# STM32WL30 register map
File version: 1.0
CPU: CM0+ r0p0, little endian, MPU, no FPU, 4 interrupt priority bits
Registers are 32-bit, read-write, reset 0x0 unless marked. A register's access mark holds for its fields unless they carry their own. Offsets are from the block's base; [hi:lo] are bit positions.

## TIM16 — TIM16 address block description
Base 0x40005000
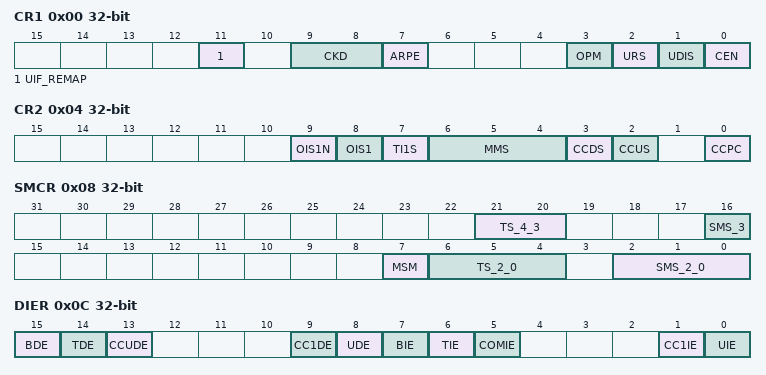
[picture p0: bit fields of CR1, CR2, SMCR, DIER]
0x00 CR1 (reset mask 0xF)
  [11] UIF_REMAP — UIFREMAP: UIF status bit remapping 0: No remapping. UIF status bit is not copied to TIMx_CNT register bit 31. 1: Remapping enabled. UIF status bit is copied to TIMx_CNT register bit 31.
  [9:8] CKD — CKD[1:0]: Clock division This bit-field indicates the division ratio between the timer clock (CK_INT) frequency and the dead-time and sampling clock (tDTS)used by the dead-time generators and the digital filters (TIx), 00: tDTS=tCK_INT 01: tDTS=2*tCK_INT 10: tDTS=4*tCK_INT 11: Reserved, do not program this value
  [7] ARPE — ARPE: Auto-reload preload enable 0: TIMx_ARR register is not buffered 1: TIMx_ARR register is buffered
  [3] OPM — OPM: One pulse mode 0: Counter is not stopped at update event. 1: Counter stops counting at the next update event (clearing the bit CEN)
  [2] URS — URS: Update request source This bit is set and cleared by software to select the UEV event sources. 0: Any of the following events generate an update interrupt or DMA request if enabled. These events can be: - Counter overflow/underflow - Setting the UG bit - Update generation through the slave mode controller 1: Only counter overflow/underflow generates an update interrupt or DMA request if enabled.
  [1] UDIS — UDIS: Update disable This bit is set and cleared by software to enable/disable UEV event generation. 0: UEV enabled. The Update (UEV) event is generated by one of the following events: - Counter overflow/underflow - Setting the UG bit - Update generation through the slave mode controller Buffered registers are then loaded with their preload values. 1: UEV disabled. The Update event is not generated, shadow registers keep their value (ARR, PSC, CCRx). However the counter and the prescaler are reinitialized if the UG bit is set or if a hardware reset is received from the slave mode controller.
  [0] CEN — CEN: Counter enable 0: Counter disabled 1: Counter enabled Note: External clock and gated mode can work only if the CEN bit has been previously set by software. However trigger mode can set the CEN bit automatically by hardware.
0x04 CR2 (reset mask 0xF)
  [9] OIS1N — OIS1N: Output Idle state 1 (OC1N output) 0: OC1N=0 after a dead-time when MOE=0 1: OC1N=1 after a dead-time when MOE=0 Note: This bit can not be modified as long as LOCK level 1, 2 or 3 has been programmed (LOCK bits in TIMx_BKR register).
  [8] OIS1 — OIS1: Output Idle state 1 (OC1 output) 0: OC1=0 (after a dead-time if OC1N is implemented) when MOE=0 1: OC1=1 (after a dead-time if OC1N is implemented) when MOE=0 Note: This bit can not be modified as long as LOCK level 1, 2 or 3 has been programmed (LOCK bits in TIMx_BKR register).
  [7] TI1S — TI1S: TI1 selection 0: The TIMx_CH1 pin is connected to TI1 input 1: Reserved
  [6:4] MMS — MMS[2:0]: Master mode selection These bits allow to select the information to be sent in master mode to slave timers for synchronization (TRGO). The combination is as follows: 000: Reset - the UG bit from the TIMx_EGR register is used as trigger output (TRGO). If the reset is generated by the trigger input (slave mode controller configured in reset mode) then the signal on TRGO is delayed compared to the actual reset. 001: Enable - the Counter Enable signal CNT_EN is used as trigger output (TRGO). It is useful to start several timers at the same time or to control a window in which a slave timer is enable. The Counter Enable signal is generated by a logic OR between CEN control bit and the trigger input when configured in gated mode. When the Counter Enable signal is controlled by the trigger input, there is a delay on TRGO, except if the master/slave mode is selected (see the MSM bit description in TIMx_SMCR register). 010: Update - The update event is selected as trigger output (TRGO). For instance a master timer can then be used as a prescaler for a slave timer. 011: Compare Pulse - The trigger output send a positive pulse when the CC1IF flag is to be set (even if it was already high), as soon as a capture or a compare match occurred. (TRGO). 100: Compare - OC1REF signal is used as trigger output (TRGO).
  [3] CCDS — CCDS: Capture/compare DMA selection 0: CCx DMA request sent when CCx event occurs 1: CCx DMA requests sent when update event occurs
  [2] CCUS — CCUS: Capture/compare control update selection 0: When capture/compare control bits are preloaded (CCPC=1), they are updated by setting the COMG bit only. 1: When capture/compare control bits are preloaded (CCPC=1), they are updated by setting the COMG bit or when an rising edge occurs on TRGI. Note: This bit acts only on channels that have a complementary output.
  [0] CCPC — CCPC: Capture/compare preloaded control 0: CCxE, CCxNE and OCxM bits are not preloaded 1: CCxE, CCxNE and OCxM bits are preloaded, after having been written, they are updated only when COM bit is set. Note: This bit acts only on channels that have a complementary output.
0x08 SMCR (reset mask 0xF)
  [21:20] TS_4_3 — TS[4:0]: Trigger selection. See TS_LSB description
  [16] SMS_3 — SMS[3:0]: Slave mode selection. See SMS_LSB description
  [7] MSM — MSM: Master/slave mode 0: No action 1: The effect of an event on the trigger input (TRGI) is delayed to allow a perfect synchronization between the current timer and its slaves (through TRGO). It is useful if we want to synchronize several timers on a single external event.
  [6:4] TS_2_0 — TS[4:0]: Trigger selection This bitfield selects the trigger input to be used to synchronize the counter. 00000: Internal Trigger 0 (ITR0) 00001: Internal Trigger 1 (ITR1) 00010: Internal Trigger 2 (ITR2) 00011: Internal Trigger 3 (ITR3) 00100: TI1 Edge Detector (TI1F_ED) 00101: Filtered Timer Input 1 (TI1FP1) Other codes: Reserved Note: These bits must be changed only when they are not used (e.g. when SMS=000) to avoid wrong edge detections at the transition. See Table 79 in IUM: TIM16 register map and reset values on page 469 for more details on ITRx meaning for each Timer.
  [2:0] SMS_2_0 — SMS[3:0]: Slave mode selection When external signals are selected the active edge of the trigger signal (TRGI) is linked to the polarity selected on the external input (see Input Control register and Control Register description.
0x0C DIER (reset mask 0xF)
  [15] BDE — BDE: Break DMA request Enable. Not used in Blue51. Not available in IUM 0: Break DMA request disabled. 1: Break DMA request enabled.
  [14] TDE — TDE: Trigger DMA request enable 0: Trigger DMA request disabled 1: Trigger DMA request enabled
  [13] CCUDE — CCUDE: CC-Update DMA request Enable. Not used in Blue51. Not available in IUM 0: CC-Update DMA request disabled. 1: CC-Update DMA request enabled.
  [9] CC1DE — CC1DE: Capture/Compare 1 DMA request enable 0: CC1 DMA request disabled 1: CC1 DMA request enabled
  [8] UDE — UDE: Update DMA request enable 0: Update DMA request disabled 1: Update DMA request enabled
  [7] BIE — BIE: Break interrupt enable 0: Break interrupt disabled 1: Break interrupt enabled
  [6] TIE — TIE: Trigger interrupt enable 0: Trigger interrupt disabled 1: Trigger interrupt enabled
  [5] COMIE — COMIE: COM interrupt enable 0: COM interrupt disabled 1: COM interrupt enabled
  [1] CC1IE — CC1IE: Capture/Compare 1 interrupt enable 0: CC1 interrupt disabled. 1: CC1 interrupt enabled
  [0] UIE — UIE: Update interrupt enable 0: Update interrupt disabled 1: Update interrupt enabled
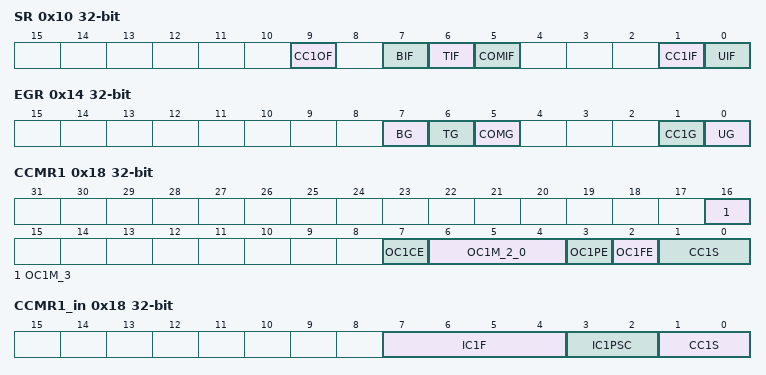
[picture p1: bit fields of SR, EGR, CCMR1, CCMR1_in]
0x10 SR (reset mask 0xF)
  [9] CC1OF — CC1OF: Capture_Compare 1 overcapture flag This flag is set by hardware only when the corresponding channel is configured in input capture mode. It is cleared by software by writing it to '0'. 0: No overcapture has been detected 1: The counter value has been captured in TIMx_CCR1 register while CC1IF flag was already set
  [7] BIF — BIF: Break interrupt flag This flag is set by hardware as soon as the break input goes active. It can be cleared by software if the break input is not active. 0: No break event occurred 1: An active level has been detected on the break input
  [6] TIF — TIF: Trigger interrupt flag This flag is set by hardware on trigger event (active edge detected on TRGI input when the slave mode controller is enabled in all modes but gated mode, both edges in case gated mode is selected). It is cleared by software. 0: No trigger event occurred 1: Trigger interrupt pending
  [5] COMIF — COMIF: COM interrupt flag This flag is set by hardware on a COM event (once the capture compare control bits CCxE, CCxNE, OCxMhave been updated). It is cleared by software. 0: No COM event occurred 1: COM interrupt pending
  [1] CC1IF — CC1IF: Capture/Compare 1 interrupt flag If channel CC1 is configured as output: This flag is set by hardware when the counter matches the compare value. It is cleared by software. 0: No match. 1: The content of the counter TIMx_CNT matches the content of the TIMx_CCR1 register. When the contents of TIMx_CCR1 are greater than the contents of TIMx_ARR, the CC1IF bit goes high on the counter overflow If channel CC1 is configured as input: This bit is set by hardware on a capture. It is cleared by software or by reading the TIMx_CCR1 register. 0: No input capture occurred 1: The counter value has been captured in TIMx_CCR1 register (An edge has been detected on IC1 which matches the selected polarity)
  [0] UIF — UIF: Update interrupt flag This bit is set by hardware on an update event. It is cleared by software. 0: No update occurred. 1: Update interrupt pending. This bit is set by hardware when the registers are updated: At overflow regarding the repetition counter value (update if repetition counter = 0) and if the UDIS=0 in the TIMx_CR1 register. When CNT is reinitialized by software using the UG bit in TIMx_EGR register, if URS=0 and UDIS=0 in the TIMx_CR1 register.
0x14 EGR (reset mask 0xF)
  [7] BG wo — BG: Break generation This bit is set by software in order to generate an event, it is automatically cleared by hardware. 0: No action. 1: A break event is generated. MOE bit is cleared and BIF flag is set. Related interrupt or DMA transfer can occur if enabled.
  [6] TG wo — TG: Trigger generation This bit is set by software in order to generate an event, it is automatically cleared by hardware. 0: No action 1: The TIF flag is set in TIMx_SR register. Related interrupt or DMA transfer can occur if enabled
  [5] COMG wo — COMG: Capture/Compare control update generation This bit can be set by software, it is automatically cleared by hardware. 0: No action 1: When the CCPC bit is set, it is possible to update the CCxE, CCxNE and OCxM bits Note: This bit acts only on channels that have a complementary output.
  [1] CC1G wo — CC1G: Capture/Compare 1 generation This bit is set by software in order to generate an event, it is automatically cleared by hardware. 0: No action. 1: A capture/compare event is generated on channel 1: If channel CC1 is configured as output: CC1IF flag is set, Corresponding interrupt or DMA request is sent if enabled. If channel CC1 is configured as input: The current value of the counter is captured in TIMx_CCR1 register. The CC1IF flag is set, the corresponding interrupt or DMA request is sent if enabled. The CC1OF flag is set if the CC1IF flag was already high.
  [0] UG wo — UG: Update generation This bit can be set by software, it is automatically cleared by hardware. 0: No action. 1: Reinitialize the counter and generates an update of the registers. Note that the prescaler counter is cleared too (anyway the prescaler ratio is not affected).
0x18 CCMR1 (reset mask 0xF)
  [16] OC1M_3 — OC1M[3]: Output Compare 1 mode (bit 3)
  [7] OC1CE — OC1CE: Output Compare 1 Clear Enable. Not used in Blue51. Not available in IUM 0: OC1REF is not affected by the ocref_clr_int signal. 1: OC1REF is cleared as soon as a high level is detected on the ocref_clr_int signal.
  [6:4] OC1M_2_0 — OC1M[2:0]: Output Compare 1 mode (bits 2 to 0) These bits define the behavior of the output reference signal OC1REF from which OC1 and OC1N are derived. OC1REF is active high whereas OC1 and OC1N active level depends on CC1P and CC1NP bits.
  [3] OC1PE — OC1PE: Output Compare 1 preload enable 0: Preload register on TIMx_CCR1 disabled. TIMx_CCR1 can be written at anytime, the new value is taken in account immediately.. 1: Preload register on TIMx_CCR1 enabled. Read/Write operations access the preload register. TIMx_CCR1 preload value is loaded in the active register at each update event. Note: 1: These bits can not be modified as long as LOCK level 3 has been programmed (LOCK bits in TIMx_BDTR register) and CC1S='00' (the channel is configured in output). Note: 2: The PWM mode can be used without validating the preload register only in one pulse mode (OPM bit set in TIMx_CR1 register). Else the behavior is not guaranteed.
  [2] OC1FE — OC1FE: Output Compare 1 fast enable This bit is used to accelerate the effect of an event on the trigger in input on the CC output. 0: CC1 behaves normally depending on counter and CCR1 values even when the trigger is ON. The minimum delay to activate CC1 output when an edge occurs on the trigger input is 5 clock cycles. 1: An active edge on the trigger input acts like a compare match on CC1 output. Then, OC is set to the compare level independently of the result of the comparison. Delay to sample the trigger input and to activate CC1 output is reduced to 3 clock cycles. OC1FE acts only if the channel is configured in PWM1 or PWM2 mode.
  [1:0] CC1S — CC1S: Capture/Compare 1 Selection This bit-field defines the direction of the channel (input/output) as well as the used input. 00: CC1 channel is configured as output 01: CC1 channel is configured as input, IC1 is mapped on TI1 1x: Reserved Note: CC1S bits are writable only when the channel is OFF (CC1E = '0' in TIMx_CCER).
0x18 CCMR1_in (reset mask 0xF) (alternate view of CCMR1)
  [7:4] IC1F — Bits 7:4 IC1F[3:0]: Input capture 1 filter This bit-field defines the frequency used to sample TI1 input and the length of the digital filter applied to TI1. The digital filter is made of an event counter in which N events are needed to validate a transition on the output: 0000: No filter, sampling is done at fDTS 0001: fSAMPLING=fCK_INT, N=2 0010: fSAMPLING=fCK_INT, N=4 0011: fSAMPLING=fCK_INT, N=8 0100: fSAMPLING=fDTS/2, N= 0101: fSAMPLING=fDTS/2, N=8 0110: fSAMPLING=fDTS/4, N=6 0111: fSAMPLING=fDTS/4, N=8 1000: fSAMPLING=fDTS/8, N=6 1001: fSAMPLING=fDTS/8, N=8 1010: fSAMPLING=fDTS/16, N=5 1011: fSAMPLING=fDTS/16, N=6 1100: fSAMPLING=fDTS/16, N=8 1101: fSAMPLING=fDTS/32, N=5 1110: fSAMPLING=fDTS/32, N=6 1111: fSAMPLING=fDTS/32, N=8
  [3:2] IC1PSC — IC1PSC: Input capture 1 prescaler This bit-field defines the ratio of the prescaler acting on CC1 input (IC1). The prescaler is reset as soon as CC1E='0' (TIMx_CCER register). 00: no prescaler, capture is done each time an edge is detected on the capture input. 01: capture is done once every 2 events 10: capture is done once every 4 events 11: capture is done once every 8 events
  [1:0] CC1S — CC1S: Capture/Compare 1 Selection This bit-field defines the direction of the channel (input/output) as well as the used input. 00: CC1 channel is configured as output 01: CC1 channel is configured as input, IC1 is mapped on TI1 1x: Reserved Note: CC1S bits are writable only when the channel is OFF (CC1E = '0' in TIMx_CCER).
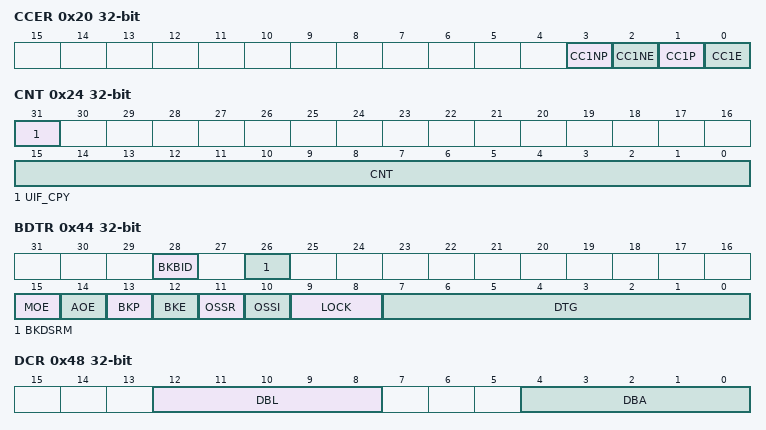
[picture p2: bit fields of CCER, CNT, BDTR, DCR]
0x20 CCER
  [3] CC1NP — CC1NP: Capture/Compare 1 complementary output polarity CC1 channel configured as output: 0: OC1N active high 1: OC1N active low CC1 channel configured as input: This bit is used in conjunction with CC1P to define the polarity of TI1FP1. Refer to the description of CC1P. Note: 1. This bit is not writable as soon as LOCK level 2 or 3 has been programmed (LOCK bits in TIMx_BDTR register) and CC1S='00' (the channel is configured in output). 2. On channels that have a complementary output, this bit is preloaded. If the CCPC bit is set in the TIMx_CR2 register then the CC1NP active bit takes the new value from the preloaded bit only when a commutation event is generated.
  [2] CC1NE — CC1NE: Capture/Compare 1 complementary output enable 0: Off - OC1N is not active. OC1N level is then function of MOE, OSSI, OSSR, OIS1, OIS1N and CC1E bits. 1: On - OC1N signal is output on the corresponding output pin depending on MOE, OSSI, OSSR, OIS1, OIS1N and CC1E bits.
  [1] CC1P — CC1P: Capture/Compare 1 output polarity CC1 channel configured as output: 0: OC1 active high 1: OC1 active low CC1 channel configured as input: The CC1NP/CC1P bits select the polarity of TI1FP1 for trigger or capture operations.. 00: Non-inverted/rising edge. The circuit is sensitive to TIxFP1 rising edge (capture or trigger operations in reset, external clock or trigger mode), TIxFP1 is not inverted (trigger operation in gated mode). 01: Inverted/falling edge. The circuit is sensitive to TIxFP1 falling edge (capture or trigger operations in reset, external clock or trigger mode), TIxFP1 is inverted (trigger operation in gated mode. 10: Reserved, do not use this configuration. (capture or trigger operations in reset, external clock or trigger mode), TIxFP1 is not inverted (trigger operation in gated mode). Note: 1. This bit is not writable as soon as LOCK level 2 or 3 has been programmed (LOCK bits in TIMx_BDTR register). 2. On channels that have a complementary output, this bit is preloaded. If the CCPC bit is set in the TIMx_CR2 register then the CC1P active bit takes the new value from the preloaded bit only when a Commutation event is generated.
    1=Non-inverted/both edges. The circuit is sensitive to both TIxFP1 rising and falling edges
  [0] CC1E — CC1E: Capture/Compare 1 output enable CC1 channel configured as output: 0: Off - OC1 is not active. OC1 level is then function of MOE, OSSI, OSSR, OIS1, OIS1N and CC1NE bits. 1: On - OC1 signal is output on the corresponding output pin depending on MOE, OSSI, OSSR, OIS1, OIS1N and CC1NE bits. CC1 channel configured as input: This bit determines if a capture of the counter value can actually be done into the input capture/compare register 1 (TIMx_CCR1) or not. 0: Capture disabled 1: Capture enabled
0x24 CNT (reset mask 0xF)
  [31] UIF_CPY ro — UIFCPY: UIF Copy This bit is a read-only copy of the UIF bit of the TIMx_ISR register. If the UIFREMAP bit in TIMx_CR1 is reset, bit 31 is reserved and read as 0.
  [15:0] CNT — CNT[15:0]: Counter value
0x28 PSC (reset mask 0xF)
  [15:0] PSC — PSC[15:0]: Prescaler value The counter clock frequency (CK_CNT) is equal to fCK_PSC / (PSC[15:0] + 1). PSC contains the value to be loaded in the active prescaler register at each update event (including when the counter is cleared through UG bit of TIMx_EGR register or through trigger controller when configured in 'reset mode').
0x2C ARR reset 0xFFFF
  [15:0] ARR — ARR[15:0]: Prescaler value ARR is the value to be loaded in the actual auto-reload register. Refer to the Section 22.3.1: Time-base unit on page 418 for more details about ARR update and behavior. The counter is blocked while the auto-reload value is null.
0x30 RCR (reset mask 0xF)
  [7:0] REP — REP[7:0]: Repetition counter value These bits allow the user to set-up the update rate of the compare registers (i.e. periodic transfers from preload to active registers) when preload registers are enable, as well as the update interrupt generation rate, if this interrupt is enable. Each time the REP_CNT related downcounter reaches zero, an update event is generated and it restarts counting from REP value. As REP_CNT is reloaded with REP value only at the repetition update event U_RC, any write to the TIMx_RCR register is not taken in account until the next repetition update event. It means in PWM mode (REP+1) corresponds to the number of PWM periods in edge-aligned mode.
0x34 CCR1 (reset mask 0xF)
  [15:0] CCR — CCR1[15:0]: Capture/Compare 1 value If channel CC1 is configured as output: CCR1 is the value to be loaded in the actual capture/compare 1 register (preload value). It is loaded permanently if the preload feature is not selected in the TIMx_CCMR1 register (bit OC1PE). Else the preload value is copied in the active capture/compare 1 register when an update event occurs. The active capture/compare register contains the value to be compared to the counter TIMx_CNT and signaled on OC1 output. If channel CC1 is configured as input: CCR1 is the counter value transferred by the last input capture 1 event (IC1).
0x44 BDTR (reset mask 0xF)
  [28] BKBID — BKBID: Break Bidirectional 0: Break input BRK in input mode 1: Break input BRK in bidirectional mode In the bidirectional mode (BKBID bit set to 1), the break input is configured both in input mode and in open drain output mode. Any active break event asserts a low logic level on the Break input to indicate an internal break event to external devices. Note: This bit cannot be modified as long as LOCK level 1 has been programmed (LOCK bits in TIMx_BDTR register). Note: Any write operation to this bit takes a delay of 1 APB clock cycle to become effective.
  [26] BKDSRM — BKDSRM: Break Disarm 0: Break input BRK is armed 1: Break input BRK is disarmed This bit is cleared by hardware when no break source is active. The BKDSRM bit must be set by software to release the bidirectional output control (opendrain output in Hi-Z state) and then be polled it until it is reset by hardware, indicating that the fault condition has disappeared. Note: Any write operation to this bit takes a delay of 1 APB clock cycle to become effective.
  [15] MOE — MOE: Main output enable This bit is cleared asynchronously by hardware as soon as the break input is active. It is set by software or automatically depending on the AOE bit. It is acting only on the channels which are configured in output. 0: OC and OCN outputs are disabled or forced to idle state depending on the OSSI bit. 1: OC and OCN outputs are enabled if their respective enable bits are set (CCxE, CCxNE in TIMx_CCER register) See OC/OCN enable description for more details (Section 22.4.8: TIM16 capture/compare enable register (TIMx_CCER)).
  [14] AOE — AOE: Automatic output enable not be active) Note: This bit can not be modified as long as LOCK level 1 has been programmed (LOCK bits in TIMx_BDTR register).
    0=MOE can be set only by software; 1=MOE can be set by software or automatically at the next update event (if the break input is
  [13] BKP — BKP: Break polarity 0: Break input BRK is active low. 1: Break input BRK is active high Note: 1. This bit can not be modified as long as LOCK level 1 has been programmed (LOCK bits in TIMx_BDTR register). Note: 2. Any write operation to this bit takes a delay of 1 APB clock cycle to become effective.
  [12] BKE — BKE: Break enable 1; Break inputs (BRK) enabled Note: 1. This bit cannot be modified when LOCK level 1 has been programmed (LOCK bits in TIMx_BDTR register). Note: 2. Any write operation to this bit takes a delay of 1 APB clock cycle to become effective.
    0=Break inputs (BRK) disabled
  [11] OSSR — OSSR: Off-state selection for Run mode This bit is used when MOE=1 on channels that have a complementary output which are configured as outputs. OSSR is not implemented if no complementary output is implemented in the timer. See OC/OCN enable description for more details (Section 22.4.8: TIM16 capture/compare enable register (TIMx_CCER)). 0: When inactive, OC/OCN outputs are disabled (the timer releases the output control which is taken over by the AFIO logic, which forces a Hi-Z state) 1: When inactive, OC/OCN outputs are enabled with their inactive level as soon as CCxE=1 or CCxNE=1 (the output is still controlled by the timer). Note: This bit can not be modified as soon as the LOCK level 2 has been programmed (LOCK bits in TIMx_BDTR register).
  [10] OSSI — OSSI: Off-state selection for Idle mode This bit is used when MOE=0 on channels configured as outputs. See OC/OCN enable description for more details (Section 22.4.8: TIM16 capture/compare enable register (TIMx_CCER)). 0: When inactive, OC/OCN outputs are disabled (OC/OCN enable output signal=0) 1: When inactive, OC/OCN outputs are forced first with their idle level as soon as CCxE=1 or CCxNE=1. OC/OCN enable output signal=1) Note: This bit can not be modified as soon as the LOCK level 2 has been programmed (LOCK bits in TIMx_BDTR register).
  [9:8] LOCK — LOCK[1:0]: Lock configuration These bits offer a write protection against software errors. 00: LOCK OFF - No bit is write protected 01: LOCK Level 1 = DTG bits in TIMx_BDTR register, OISx and OISxN bits in TIMx_CR2 register, BKE/BKP/AOE/BKBID/BKDSRM bits in TIMx_BDTR register and all used bits in TIMx_AF1 register can no longer be written. 10: LOCK Level 2 = LOCK Level 1 + CC Polarity bits (CCxP/CCxNP bits in TIMx_CCER register, as long as the related channel is configured in output through the CCxS bits) as well as OSSR and OSSI bits can no longer be written. 11: LOCK Level 3 = LOCK Level 2 + CC Control bits (OCxM and OCxPE bits in TIMx_CCMRx registers, as long as the related channel is configured in output through the CCxS bits) can no longer be written. Note: The LOCK bits can be written only once after the reset. Once the TIMx_BDTR register has been written, their content is frozen until the next reset.
  [7:0] DTG — DTG[7:0]: Dead-time generator setup This bit-field defines the duration of the dead-time inserted between the complementary outputs. DT correspond to this duration. DTG[7:5]=0xx => DT=DTG[7:0]x tdtg with tdtg=tDTS DTG[7:5]=10x => DT=(64+DTG[5:0])xtdtg with Tdtg=2xtDTS DTG[7:5]=110 => DT=(32+DTG[4:0])xtdtg with Tdtg=8xtDTS DTG[7:5]=111 => DT=(32+DTG[4:0])xtdtg with Tdtg=16xtDTS Example if TDTS=125ns (8MHz), dead-time possible values are: 0 to 15875 ns by 125 ns steps, 16 us to 31750 ns by 250 ns steps, 32 us to 63 us by 1 us steps, 64 us to 126 us by 2 us steps Note: This bit-field can not be modified as long as LOCK level 1, 2 or 3 has been programmed (LOCK bits in TIMx_BDTR register).
0x48 DCR (reset mask 0xF)
  [12:8] DBL — DBL[4:0]: DMA burst length This 5-bit field defines the length of DMA transfers (the timer recognizes a burst transfer when a read or a write access is done to the TIMx_DMAR address), i.e. the number of transfers. Transfers can be in half-words or in bytes (see example below). 00000: 1 transfer, 00001: 2 transfers, 00010: 3 transfers, ... 10001: 18 transfers.
  [4:0] DBA — DBA[4:0]: DMA base address This 5-bit field defines the base-address for DMA transfers (when read/write access are done through the TIMx_DMAR address). DBA is defined as an offset starting from the address of the TIMx_CR1 register. Example: 00000: TIMx_CR1, 00001: TIMx_CR2, 00010: Reserved, ... Example: Let us consider the following transfer: DBL = 7 transfers and DBA = TIMx_CR1. In this case the transfer is done to/from 7 registers starting from the TIMx_CR1 address.
0x4C DMAR (reset mask 0xF)
  [15:0] DMAB — DMAB[15:0]: DMA register for burst accesses A read or write operation to the DMAR register accesses the register located at the address (TIMx_CR1 address) + (DBA + DMA index) x 4 where TIMx_CR1 address is the address of the control register 1, DBA is the DMA base address configured in TIMx_DCR register, DMA index is automatically controlled by the DMA transfer, and ranges from 0 to DBL (DBL configured in TIMx_DCR).
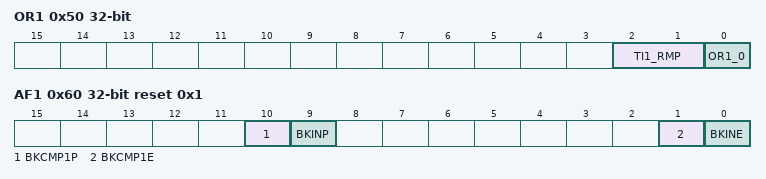
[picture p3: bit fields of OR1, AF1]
0x50 OR1
  [2:1] TI1_RMP — TI1_RMP[1:0]: Timer 16 input 1 connection This bit is set and cleared by software. 00: TIM16 TI1 is connected to GPIO 01: TIM16 TI1 is connected to LCO 10: TIM16 TI1 is connected to COMP_OUT 11: TIM16 TI1 is connected to MCO
  [0] OR1_0 — Not used in Blue51. Not available in IUM
0x60 AF1 reset 0x1 (reset mask 0xF)
  [10] BKCMP1P — BKCMP1P: BRK COMP1 input polarity. This bit selects the COMP1 input sensitivity. It must be programmed together with the BKP polarity bit. 0: COMP1 input is active low. 1: COMP1 input is active high. Note: This bit can not be modified as long as LOCK level 1 has been programmed (LOCK bits in TIMx_BDTR register)
  [9] BKINP — BKINP: BRK BKIN input polarity. This bit selects the BKIN alternate function input sensitivity. It must be programmed together with the BKP polarity bit. 0: BKIN input is active low. 1: BKIN input is active high. Note: This bit can not be modified as long as LOCK level 1 has been programmed (LOCK bits in TIMx_BDTR register)
  [1] BKCMP1E — BKCMP1E: BRK COMP1 enable. This bit enables the COMP1 for the timer's BRK input. COMP1 output is ORed with the other enabled BRK sources. 0: COMP1 input disabled. 1: COMP1 input enabled. Note: This bit can not be modified as long as LOCK level 1 has been programmed (LOCK bits in TIMx_BDTR register)
  [0] BKINE — BKINE: BRK BKIN enable. This bit enables the BKIN alternate function input for the timer's BRK input. BKIN input is ORed with the other enabled BRK sources. 0: BKIN input disabled. 1: BKIN input enabled. Note: This bit can not be modified as long as LOCK level 1 has been programmed (LOCK bits in TIMx_BDTR register)
0x68 TISEL
  [3:0] TI1SEL — TI1SEL[3:0]: selects TI1[0] to TI1[15] input 0000: TIMx_CH1 input Others: Reserved
